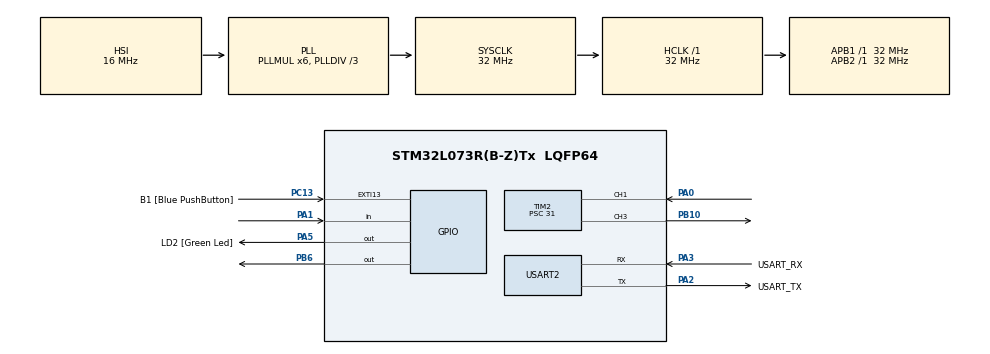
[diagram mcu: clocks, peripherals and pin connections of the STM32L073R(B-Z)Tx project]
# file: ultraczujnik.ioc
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Mcu.Family=STM32L0
Mcu.Name=STM32L073R(B-Z)Tx
Mcu.Package=LQFP64
PA0.Signal=S_TIM2_CH1
PA1.Signal=GPIO_Input
PA13.GPIO_Label=TMS
PA13.Signal=SYS_SWDIO
PA14.GPIO_Label=TCK
PA14.Signal=SYS_SWCLK
PA2.GPIO_Label=USART_TX
PA2.Mode=Asynchronous
PA2.Signal=USART2_TX
PA3.GPIO_Label=USART_RX
PA3.Mode=Asynchronous
PA3.Signal=USART2_RX
PA5.GPIO_Label=LD2 [Green Led]
PA5.Signal=GPIO_Output
PB10.Signal=S_TIM2_CH3
PB6.Signal=GPIO_Output
PC13.GPIO_Label=B1 [Blue PushButton]
PC13.GPIO_ModeDefaultEXTI=GPIO_MODE_IT_FALLING
PC13.Signal=GPXTI13
PC14-OSC32_IN.Signal=RCC_OSC32_IN
PC15-OSC32_OUT.Signal=RCC_OSC32_OUT
PH0-OSC_IN.GPIO_Label=MCO
PH0-OSC_IN.Signal=RCC_OSC_IN
ProjectManager.HeapSize=0x200
ProjectManager.StackSize=0x400
ProjectManager.TargetToolchain=STM32CubeIDE
RCC.AHBFreq_Value=32000000
RCC.APB1Freq_Value=32000000
RCC.APB1TimFreq_Value=32000000
RCC.APB2Freq_Value=32000000
RCC.APB2TimFreq_Value=32000000
RCC.HCLKFreq_Value=32000000
RCC.HSE_VALUE=8000000
RCC.HSI16_VALUE=16000000
RCC.HSI48_VALUE=48000000
RCC.HSI_VALUE=16000000
RCC.LSEState=RCC_LSE_ON
RCC.LSE_VALUE=32768
RCC.MSI_VALUE=2097000
RCC.PLLDIV=RCC_PLLDIV_3
RCC.PLLMUL=RCC_PLLMUL_6
RCC.SYSCLKFreq_VALUE=32000000
RCC.SYSCLKSource=RCC_SYSCLKSOURCE_PLLCLK
RCC.VCOOutputFreq_Value=96000000
SH.S_TIM2_CH1.0=TIM2_CH1,Input_Capture1_from_TI1
SH.S_TIM2_CH3.0=TIM2_CH3,PWM Generation3 CH3
TIM2.Channel-Input_Capture1_from_TI1=TIM_CHANNEL_1
TIM2.Channel-Input_Capture2_from_TI1_63=TIM_CHANNEL_2
TIM2.Channel-PWM\ Generation3\ CH3=TIM_CHANNEL_3
TIM2.ICPolarity_CH2=TIM_INPUTCHANNELPOLARITY_FALLING
TIM2.Prescaler=31
TIM2.Pulse-PWM\ Generation3\ CH3=10
USART2.VirtualMode-Asynchronous=VM_ASYNC
VP_TIM2_VS_indirect_ch1.Mode=Input_Capture2_from_TI1_63
board=NUCLEO-L073RZ

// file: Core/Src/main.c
/* USER CODE BEGIN Header */
/**
  ******************************************************************************
  * @file           : main.c
  * @brief          : Main program body
  ******************************************************************************
  * @attention
  *
  * Copyright (c) 2022 STMicroelectronics.
  * All rights reserved.
  *
  * This software is licensed under terms that can be found in the LICENSE file
  * in the root directory of this software component.
  * If no LICENSE file comes with this software, it is provided AS-IS.
  *
  ******************************************************************************
  */
/* USER CODE END Header */
#include "main.h"
#include "tim.h"
#include "usart.h"
#include "gpio.h"

/* USER CODE BEGIN Includes */
#include <stdio.h>
/* USER CODE END Includes */

/* USER CODE BEGIN PV */
char msg[64];
/* USER CODE END PV */

void SystemClock_Config(void);

int main(void)
{

  /* MCU Configuration--------------------------------------------------------*/

  /* Reset of all peripherals, Initializes the Flash interface and the Systick. */
  HAL_Init();

  /* Configure the system clock */
  SystemClock_Config();

  /* Initialize all configured peripherals */
  MX_GPIO_Init();
  MX_TIM2_Init();
  MX_USART2_UART_Init();

  /* Infinite loop */
  /* USER CODE BEGIN WHILE */
  HAL_TIM_IC_Start(&htim2, TIM_CHANNEL_1);
 // HAL_TIM_IC_Start(&htim2, TIM_CHANNEL_2);
  HAL_TIM_PWM_Start(&htim2, TIM_CHANNEL_3);
  HAL_Delay(1000);
  while (1)
  {
	  uint32_t start = HAL_TIM_ReadCapturedValue(&htim2, TIM_CHANNEL_1);
	  	//uint32_t stop = HAL_TIM_ReadCapturedValue(&htim2, TIM_CHANNEL_2);
	  sprintf((char*)msg,"Odczyt: %lu\n",start);
	  //	sprintf((char*)msg,"Odczyt: %.1f cm\n",(stop - start) / 58.0f);
	  	HAL_UART_Transmit(&huart2, (uint8_t*)msg, strlen(msg),1000);
	  	HAL_Delay(65);
    /* USER CODE END WHILE */

  }
}

void SystemClock_Config(void)
{
  RCC_OscInitTypeDef RCC_OscInitStruct = {0};
  RCC_ClkInitTypeDef RCC_ClkInitStruct = {0};
  RCC_PeriphCLKInitTypeDef PeriphClkInit = {0};

  /** Configure the main internal regulator output voltage
  */
  __HAL_PWR_VOLTAGESCALING_CONFIG(PWR_REGULATOR_VOLTAGE_SCALE1);

  /** Initializes the RCC Oscillators according to the specified parameters
  * in the RCC_OscInitTypeDef structure.
  */
  RCC_OscInitStruct.OscillatorType = RCC_OSCILLATORTYPE_HSI;
  RCC_OscInitStruct.HSIState = RCC_HSI_ON;
  RCC_OscInitStruct.HSICalibrationValue = RCC_HSICALIBRATION_DEFAULT;
  RCC_OscInitStruct.PLL.PLLState = RCC_PLL_ON;
  RCC_OscInitStruct.PLL.PLLSource = RCC_PLLSOURCE_HSI;
  RCC_OscInitStruct.PLL.PLLMUL = RCC_PLLMUL_6;
  RCC_OscInitStruct.PLL.PLLDIV = RCC_PLLDIV_3;
  if (HAL_RCC_OscConfig(&RCC_OscInitStruct) != HAL_OK)
  {
    Error_Handler();
  }

  /** Initializes the CPU, AHB and APB buses clocks
  */
  RCC_ClkInitStruct.ClockType = RCC_CLOCKTYPE_HCLK|RCC_CLOCKTYPE_SYSCLK
                              |RCC_CLOCKTYPE_PCLK1|RCC_CLOCKTYPE_PCLK2;
  RCC_ClkInitStruct.SYSCLKSource = RCC_SYSCLKSOURCE_PLLCLK;
  RCC_ClkInitStruct.AHBCLKDivider = RCC_SYSCLK_DIV1;
  RCC_ClkInitStruct.APB1CLKDivider = RCC_HCLK_DIV1;
  RCC_ClkInitStruct.APB2CLKDivider = RCC_HCLK_DIV1;

  if (HAL_RCC_ClockConfig(&RCC_ClkInitStruct, FLASH_LATENCY_1) != HAL_OK)
  {
    Error_Handler();
  }
  PeriphClkInit.PeriphClockSelection = RCC_PERIPHCLK_USART2;
  PeriphClkInit.Usart2ClockSelection = RCC_USART2CLKSOURCE_PCLK1;
  if (HAL_RCCEx_PeriphCLKConfig(&PeriphClkInit) != HAL_OK)
  {
    Error_Handler();
  }
}

void Error_Handler(void)
{
  __disable_irq();
  while (1)
  {
  }
}
